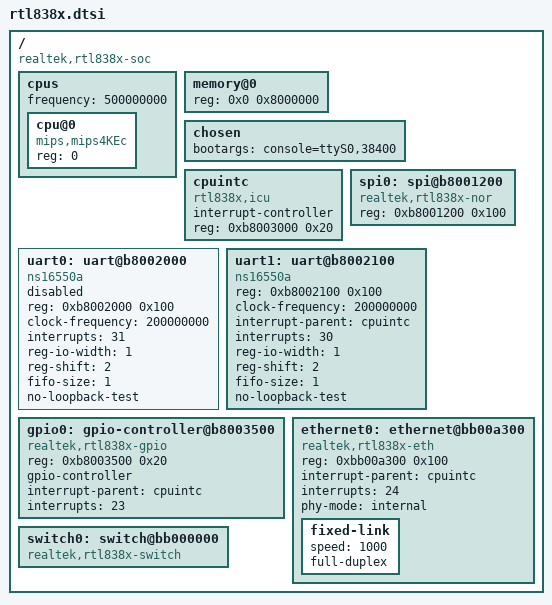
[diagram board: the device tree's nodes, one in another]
// SPDX-License-Identifier: GPL-2.0-or-later OR MIT

/dts-v1/;

/ {
	#address-cells = <1>;
	#size-cells = <1>;

	compatible = "realtek,rtl838x-soc";

	cpus {
		#address-cells = <1>;
		#size-cells = <0>;
		frequency = <500000000>;

		cpu@0 {
			compatible = "mips,mips4KEc";
			reg = <0>;
		};
	};

	memory@0 {
		device_type = "memory";
		reg = <0x0 0x8000000>;
	};

	chosen {
		bootargs = "console=ttyS0,38400";
	};

	cpuintc: cpuintc {
		#address-cells = <0>;
		#interrupt-cells = <1>;
		interrupt-controller;
		compatible = "rtl838x,icu";
		reg = <0xb8003000 0x20>;
	};

	spi0: spi@b8001200 {
		status = "okay";

		compatible = "realtek,rtl838x-nor";
		reg = <0xb8001200 0x100>;

		#address-cells = <1>;
		#size-cells = <0>;
	};

	uart0: uart@b8002000 {
		status = "disabled";

		compatible = "ns16550a";
		reg = <0xb8002000 0x100>;

		clock-frequency = <200000000>;
		interrupts = <31>;

		reg-io-width = <1>;
		reg-shift = <2>;
		fifo-size = <1>;
		no-loopback-test;
	};

	uart1: uart@b8002100 {
		status = "okay";

		compatible = "ns16550a";
		reg = <0xb8002100 0x100>;

		clock-frequency = <200000000>;

		interrupt-parent = <&cpuintc>;
		interrupts = <30>;

		reg-io-width = <1>;
		reg-shift = <2>;
		fifo-size = <1>;
		no-loopback-test;
	};

	gpio0: gpio-controller@b8003500 {
		compatible = "realtek,rtl838x-gpio";
		reg = <0xb8003500 0x20>;
		gpio-controller;
		#gpio-cells = <2>;
		interrupt-parent = <&cpuintc>;
		interrupts = <23>;
	};

	ethernet0: ethernet@bb00a300 {
		status = "okay";

		compatible = "realtek,rtl838x-eth";
		reg = <0xbb00a300 0x100>;
		interrupt-parent = <&cpuintc>;
		interrupts = <24>;
		#interrupt-cells = <1>;
		phy-mode = "internal";

		fixed-link {
			speed = <1000>;
			full-duplex;
		};
	};

	switch0: switch@bb000000 {
		status = "okay";

		compatible = "realtek,rtl838x-switch";
	};
};
